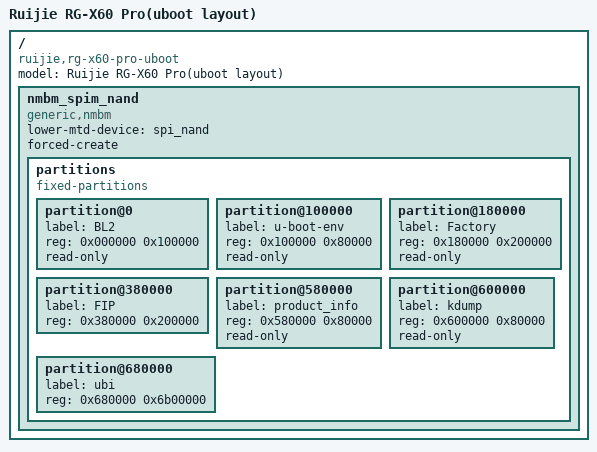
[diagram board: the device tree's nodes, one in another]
// SPDX-License-Identifier: (GPL-2.0 OR MIT)

/dts-v1/;
#include "mt7986a-ruijie-rg-x60-pro.dtsi"

/ {
	compatible = "ruijie,rg-x60-pro-uboot", "mediatek,mt7986a";
 	model = "Ruijie RG-X60 Pro(uboot layout)";

	nmbm_spim_nand {
		compatible = "generic,nmbm";
		#address-cells = <1>;
		#size-cells = <1>;

		lower-mtd-device = <&spi_nand>;
		forced-create;

		partitions {
			compatible = "fixed-partitions";
			#address-cells = <0x01>;
			#size-cells = <0x01>;

			
 			partition@0 {
 				label = "BL2";
 				reg = <0x000000 0x100000>;
 				read-only;
 			};

 			partition@100000 {
 				label = "u-boot-env";
 				reg = <0x100000 0x80000>;
 				read-only;
 			};

 			partition@180000 {
 				label = "Factory";
 				reg = <0x180000 0x200000>;
 				read-only;
 			};
			
 			partition@380000 {
 				label = "FIP";
 				reg = <0x380000 0x200000>;
 			};

 			partition@580000 {
 				label = "product_info";
 				reg = <0x580000 0x80000>;
 				read-only;
 			};

 			partition@600000 {
 				label = "kdump";
 				reg = <0x600000 0x80000>;
 				read-only;
 			};

 			partition@680000 {
 				label = "ubi";
 				reg = <0x680000 0x6b00000>;
 			};

		};
	};
};
